# soc-perf-c809403 register map
Vendor: litex
Registers are 32-bit, read-write, reset 0x0 unless marked. A register's access mark holds for its fields unless they carry their own. Offsets are from the block's base; [hi:lo] are bit positions; {n}, {i} and the like mark numbered series; 'fields as' and 'values as' point back to an identical list.

## TRNG_SERVER
Base 0xF001D000
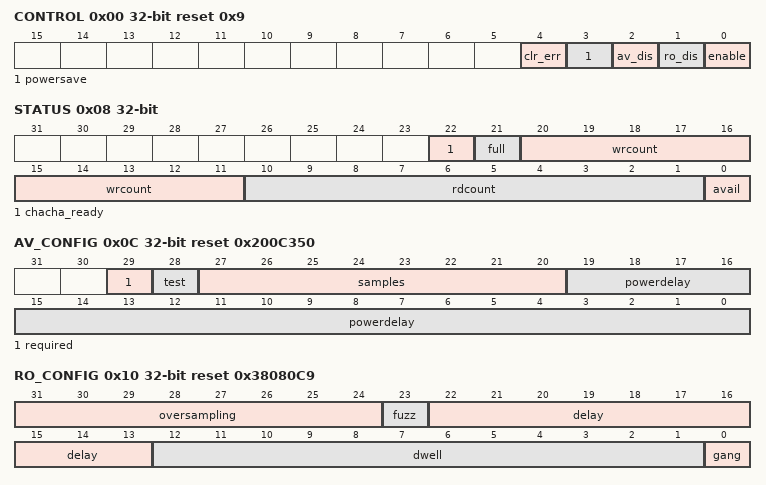
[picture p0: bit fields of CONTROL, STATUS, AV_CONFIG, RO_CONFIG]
0x00 CONTROL reset 0x9
  [4] clr_err — Write ``1`` to this bit to clear the ``errors`` register
  [3] powersave — When set, TRNGs are automatically turned off until the low water mark is hit; when cleared, TRNGs are always on
  [2] av_dis — When set, disables the avalanche generator as an entropy source
  [1] ro_dis — When set, disables the ring oscillator as an entropy source
  [0] enable — Power on the management interface and auto-fill random numbers
0x04 DATA
  [31:0] data — Latest random data from the FIFO; only valid if available bit is set Unlike the kernel's raw data port, this one is safe to use as there is no race condition with the reseeding algorithm. That being said, it is preferred to use `urandom` because the Conditioner protects against unanticipated dropouts in the raw TRNG stream.
0x08 STATUS
  [22] chacha_ready — Chacha conditioner is seeded and ready
  [21] full — Both kernel and server FIFOs have been topped off
  [20:11] wrcount — Write fifo pointer
  [10:1] rdcount — Read fifo pointer
  [0] avail — FIFO data is available
0x0C AV_CONFIG reset 0x200C350
  [29] required — Require avalanche generator to work in order for boot (used by the synthetic test bench as this self-test 'runs long' compared to the other operations)
  [28] test — When set, puts the generator into test mode -- full-size, raw ADC samples are directly placed into the FIFO at full rate, creating a 'virtual oscilloscope' snapshot of the avalanche generator waveform.
  [27:20] samples — Number of samples to fold into a single result. Smaller values increase rate but decrease quality. Default is 32.
  [19:0] powerdelay — Delay in microseconds for avalanche generator to stabilize
0x10 RO_CONFIG reset 0x38080C9
  [31:24] oversampling — Number of stages to oversample entropy. Normally, each bit is just sampled and shifted once (so 32 times for 32-bit word). Each increment of oversampling will add another stage.
  [23] fuzz — Modulate the `delay`/`dwell` parameter slightly from run-to-run, based on previous run's random values. May help to break ring oscillator resonances trained by the delay/dwell periodicity.
  [22:13] delay — Sampler delay time. Sets the delay between when the small rings are merged together, and when the final entropy result is sampled. Value encodes number of sysclk edges to pass during the delay period. Delay should be long enough for the signal to propagate around the merged ring, but longer times also means more coupling of the deterministic sysclk noise into the rings.
  [12:1] dwell — Prescaler to set dwell-time of entropy collection. Controls the period of how long the oscillators are in a metastable state to collect entropy before sampling. Value encodes the number of sysclk edges to pass during the dwell period.
  [0] gang — Fold in collective gang entropy during dwell time
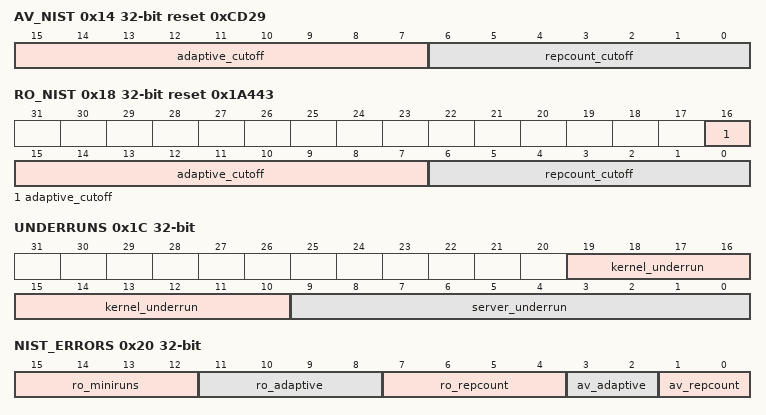
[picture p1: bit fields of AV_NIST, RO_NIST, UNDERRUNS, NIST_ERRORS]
0x14 AV_NIST reset 0xCD29
  [15:7] adaptive_cutoff — Sets the `C` (cutoff) parameter in the NIST adaptive proportion test for the avalanche generator
  [6:0] repcount_cutoff — Sets the `C` (cutoff) parameter in the NIST repetition count test for the avalanche generator
0x18 RO_NIST reset 0x1A443
  [16:7] adaptive_cutoff — Sets the `C` (cutoff) parameter in the NIST adaptive proportion test for the ringosg generator
  [6:0] repcount_cutoff — Sets the `C` (cutoff) parameter in the NIST repetition count test for the ringosc generator
0x1C UNDERRUNS
  [19:10] kernel_underrun — If non-zero, a kernel underrun has occurred. Will count number of underruns up to max field size
  [9:0] server_underrun — If non-zero, a server underrun has occurred. Will count number of underruns up to max field size
0x20 NIST_ERRORS
  [15:12] ro_miniruns — Indicates a failure in the miniruns test
  [11:8] ro_adaptive — Indicates a failure in the adaptive proportion test for the ring oscillators
  [7:4] ro_repcount — Indicates a failure in the repcount test for the ring oscillators
  [3:2] av_adaptive — Indicates a failure in a adaptive proportion test for one of two avalanche generators
  [1:0] av_repcount — Indicates a failure in a repcount test for one of two avalanche generators
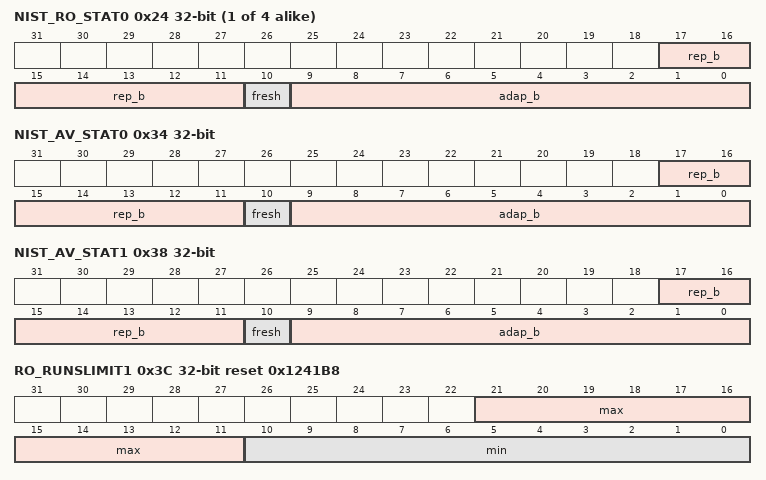
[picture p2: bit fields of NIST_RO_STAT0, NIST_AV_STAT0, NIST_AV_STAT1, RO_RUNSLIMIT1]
{0x24+4i} NIST_RO_STAT{i} (i=0..3)
  [17:11] rep_b — max `b` value for core 0 repetition count test
  [10] fresh — when `1`, adaptive proprotion b has been updated since last read
  [9:0] adap_b — last window's `b` value for core {i} adaptive proportion test
0x34 NIST_AV_STAT0
  [17:11] rep_b — max `b` value for core 0 repetition count test
  [10] fresh — when `1`, adaptive proprotion b has been updated since last read
  [9:0] adap_b — last window's `b` value for core 0 adaptive proportion test
0x38 NIST_AV_STAT1
  fields as NIST_AV_STAT0
0x3C RO_RUNSLIMIT1 reset 0x1241B8
  [21:11] max — Minimum runs limit for runs of length 1
  [10:0] min — Minimum runs limit for runs of length 1
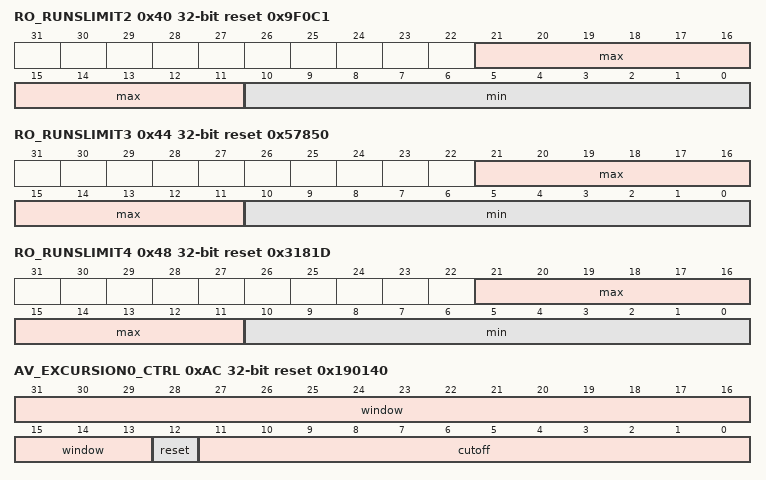
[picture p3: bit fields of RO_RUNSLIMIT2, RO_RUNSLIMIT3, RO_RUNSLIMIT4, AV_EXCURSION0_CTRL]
0x40 RO_RUNSLIMIT2 reset 0x9F0C1
  [21:11] max — Minimum runs limit for runs of length 2
  [10:0] min — Minimum runs limit for runs of length 2
0x44 RO_RUNSLIMIT3 reset 0x57850
  [21:11] max — Minimum runs limit for runs of length 3
  [10:0] min — Minimum runs limit for runs of length 3
0x48 RO_RUNSLIMIT4 reset 0x3181D
  [21:11] max — Minimum runs limit for runs of length 4
  [10:0] min — Minimum runs limit for runs of length 4
{0x4C+0x18*i} RO_RUN{i}_CTRL reset 0x3FF (i=0..3)
  [10:0] window — Number of samples over which to measure. Must be less than 2047, or else undefined behavior occurs
{0x50+0x18*i} RO_RUN{i}_FRESH (i=0..3) — The current data corresponding to a runlength of (bitposition +1) has been updated at least once since the last readout of any register
  [3:0] ro_run{i}_fresh
{0x54+0x18*i} RO_RUN{i}_COUNT1 (i=0..3) — Count of sequence length 1 runs seen in the past window
  [10:0] ro_run{i}_count1
{0x58+0x18*i} RO_RUN{i}_COUNT2 (i=0..3) — Count of sequence length 2 runs seen in the past window
  [10:0] ro_run{i}_count2
{0x5C+0x18*i} RO_RUN{i}_COUNT3 (i=0..3) — Count of sequence length 3 runs seen in the past window
  [10:0] ro_run{i}_count3
{0x60+0x18*i} RO_RUN{i}_COUNT4 (i=0..3) — Count of sequence length 4 runs seen in the past window
  [10:0] ro_run{i}_count4
0xAC AV_EXCURSION0_CTRL reset 0x190140
  [31:13] window — Number of samples over which to measure
  [12] reset — Write `1` to reset the system, including any error flags
  [11:0] cutoff — Minimum excursion required to pass
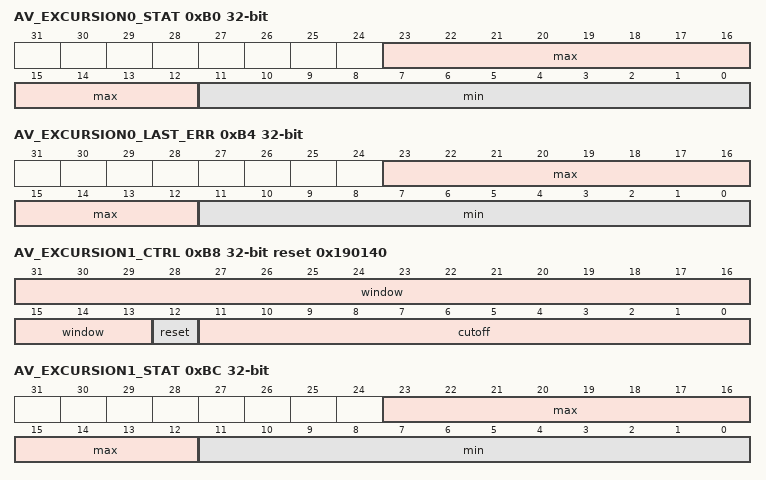
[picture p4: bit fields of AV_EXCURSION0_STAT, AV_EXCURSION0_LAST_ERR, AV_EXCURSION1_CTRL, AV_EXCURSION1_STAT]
0xB0 AV_EXCURSION0_STAT
  [23:12] max — Maximum of last window
  [11:0] min — Minimum of last window
0xB4 AV_EXCURSION0_LAST_ERR
  [23:12] max — Maximum of last error window
  [11:0] min — Minimum of last error window
0xB8 AV_EXCURSION1_CTRL reset 0x190140
  fields as AV_EXCURSION0_CTRL
0xBC AV_EXCURSION1_STAT
  fields as AV_EXCURSION0_STAT
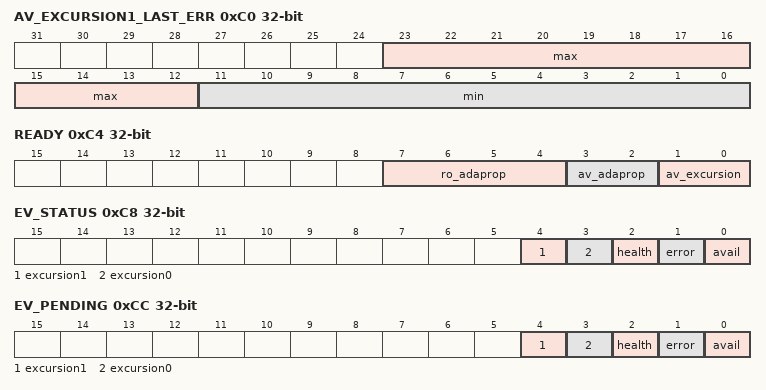
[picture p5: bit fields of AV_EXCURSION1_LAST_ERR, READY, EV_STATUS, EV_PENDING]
0xC0 AV_EXCURSION1_LAST_ERR
  fields as AV_EXCURSION0_LAST_ERR
0xC4 READY
  [7:4] ro_adaprop — ready bits from the adaptive proportion test
  [3:2] av_adaprop — ready bits from the adaptive proportion test
  [1:0] av_excursion — ready bits from the excursion test
0xC8 EV_STATUS — Triggered by a failure in the avalanche generator core 1 on-line excursion test
  [4] excursion1 — Level of the ``excursion1`` event
  [3] excursion0 — Level of the ``excursion0`` event
  [2] health — Level of the ``health`` event
  [1] error — Level of the ``error`` event
  [0] avail — Level of the ``avail`` event
0xCC EV_PENDING — Triggered by a failure in the avalanche generator core 1 on-line excursion test
  [4] excursion1 — Triggered by a failure in the avalanche generator core 1 on-line excursion test
  [3] excursion0 — Triggered by a failure in the avalanche generator core 0 on-line excursion test
  [2] health — Triggered whenever a health event first occurs
  [1] error — Triggered whenever an error condition first occurs on the server interface
  [0] avail — Triggered anytime there is data available on the server interface
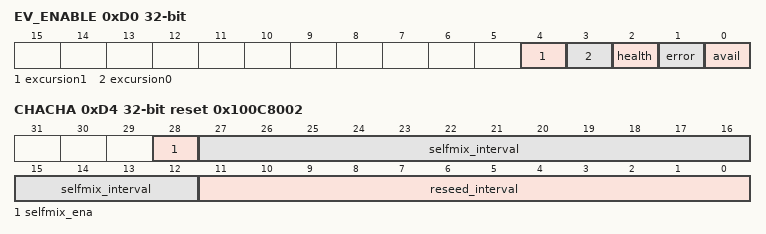
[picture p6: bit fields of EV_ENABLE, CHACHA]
0xD0 EV_ENABLE — Triggered by a failure in the avalanche generator core 1 on-line excursion test
  [4] excursion1 — Write a ``1`` to enable the ``excursion1`` Event
  [3] excursion0 — Write a ``1`` to enable the ``excursion0`` Event
  [2] health — Write a ``1`` to enable the ``health`` Event
  [1] error — Write a ``1`` to enable the ``error`` Event
  [0] avail — Write a ``1`` to enable the ``avail`` Event
0xD4 CHACHA reset 0x100C8002
  [28] selfmix_ena — Enable self mixing feature
  [27:12] selfmix_interval — How many sysclk cycles in between automatic round advancement (adjust to reduce standby power)
  [11:0] reseed_interval — How many ChaCha blocks to generate before automatically rotating the key pool
0xD8 SEED — Extra data to be rotated into the seed pool. This is supplemental to the automatically seeded TRNG data. Data is committed to the pool immediately upon write.
0xDC URANDOM — Unlimited random numbers, output from the ChaCha conditioner. Generally, you want to use this.
0xE0 URANDOM_VALID — Set when `urandom` is valid. Always check before taking `urandom`
  [0] urandom_valid
0xE4 TEST
  [0] simultaneous — Force a simultaneous advance of kernel/user urandom. Used to exercise a corner case in testing. Not harmful in production, just wasteful.
